# TMS320F280049 register map
Vendor: Texas Instruments; Series: C2000 F28004x; File version: 0.2.0-generated
Registers are 16-bit, read-write, reset 0x0 unless marked. A register's access mark holds for its fields unless they carry their own. Offsets are from the block's base; [hi:lo] are bit positions; 'fields as' and 'values as' point back to an identical list.

## PGA1REGS — PGA Registers
Base 0x0000B600
Same registers: PGA2REGS 0x0000B620, PGA3REGS 0x0000B640, PGA4REGS 0x0000B660, PGA5REGS 0x0000B680, PGA6REGS 0x0000B6A0, PGA7REGS 0x0000B6C0
0x00 PGACTL 32-bit — PGA Control Register
  [9:7] GAIN — PGA gain setting
  [7:4] FILTRESSEL — Filter Resistor Select
  [0] PGAEN — PGA Enable
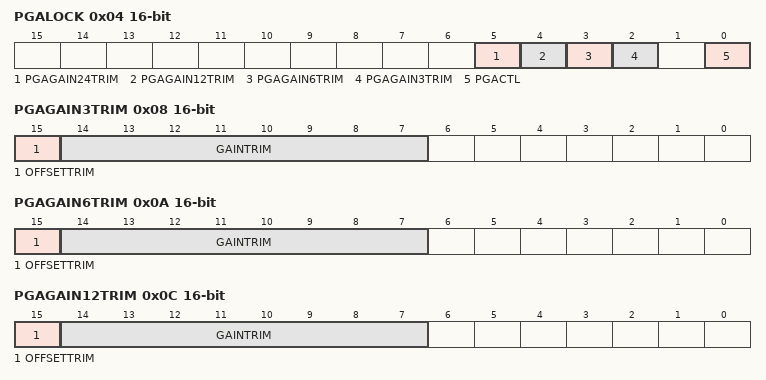
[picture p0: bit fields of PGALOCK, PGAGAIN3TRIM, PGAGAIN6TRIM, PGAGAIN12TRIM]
0x04 PGALOCK
  [5] PGAGAIN24TRIM — Lock bit for PGAGAIN24TRIM.
  [4] PGAGAIN12TRIM — Lock bit for PGAGAIN12TRIM.
  [3] PGAGAIN6TRIM — Lock bit for PGAGAIN6TRIM.
  [2] PGAGAIN3TRIM — Lock bit for PGAGAIN3TRIM.
  [0] PGACTL — Lock bit for PGACTL.
0x08 PGAGAIN3TRIM — PGA Gain Trim Register for a gain setting of 3
  [15] OFFSETTRIM — OFFSET TRIM value, when Gain setting is 3
  [14:7] GAINTRIM — Gain TRIM value, when gain setting is 3
0x0A PGAGAIN6TRIM — PGA Gain Trim Register for a gain setting of 6
  [15] OFFSETTRIM — OFFSET TRIM value, when Gain setting is 6
  [14:7] GAINTRIM — Gain TRIM value, when gain setting is 6
0x0C PGAGAIN12TRIM — PGA Gain Trim Register for a gain setting of 12
  [15] OFFSETTRIM — OFFSET TRIM value, when Gain setting is 12
  [14:7] GAINTRIM — Gain TRIM value, when gain setting is 12
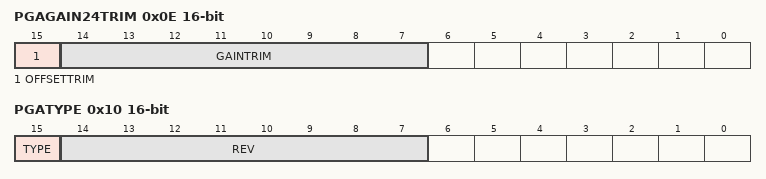
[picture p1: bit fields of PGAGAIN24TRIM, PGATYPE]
0x0E PGAGAIN24TRIM — PGA Gain Trim Register for a gain setting of 24
  [15] OFFSETTRIM — OFFSET TRIM value, when Gain setting is 24
  [14:7] GAINTRIM — Gain TRIM value, when gain setting is 24
0x10 PGATYPE
  [15] TYPE — PGA Type Field
  [14:7] REV — PGA Revision Field

## DACAREGS — DAC Registers
Base 0x0000B800
Same registers: DACBREGS 0x0000B820
0x00 DACREV — DAC Revision Register
  [14:7] REV
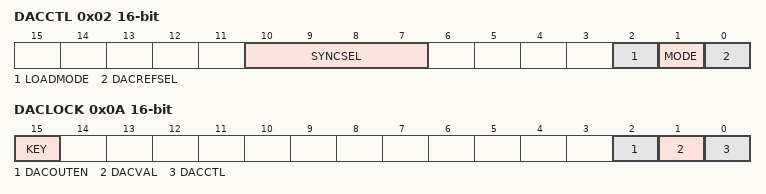
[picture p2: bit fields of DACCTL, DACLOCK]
0x02 DACCTL — DAC Control Register
  [10:7] SYNCSEL — DAC EPWMSYNCPER Select
  [2] LOADMODE — DACVALA Load Mode
  [1] MODE — DAC Mode Select
  [0] DACREFSEL — DAC Reference Select
0x04 DACVALA — DAC Value Register - Active
  [15:11] DACVALA — DAC Active Output Code
0x06 DACVALS — DAC Value Register - Shadow
  [15:11] DACVALS — DAC Shadow Output Code
0x08 DACOUTEN — DAC Output Enable Register
  [0] DACOUTEN — DAC Output Code
0x0A DACLOCK
  [15] KEY — DAC Register Lock Key
  [2] DACOUTEN — DAC Output Enable Register Lock
  [1] DACVAL — DAC Value Register Lock
  [0] DACCTL — DAC Control Register Lock
0x0C DACTRIM
  [14:7] OFFSET_TRIM — DAC Offset Trim

## CMPSS1REGS — CMPSS Registers
Base 0x0000B900
Same registers: CMPSS2REGS 0x0000B940, CMPSS3REGS 0x0000B980, CMPSS4REGS 0x0000B9C0, CMPSS5REGS 0x0000BA00, CMPSS6REGS 0x0000BA40, CMPSS7REGS 0x0000BA80
0x00 COMPCTL — CMPSS Comparator Control Register
  [15] COMPDACE — Comparator/DAC Enable
  [14] ASYNCLEN — Low Comparator Asynchronous Path Enable
  [14:13] CTRIPOUTLSEL — Low Comparator Trip Output Select
  [12:11] CTRIPLSEL — Low Comparator Trip Select
  [9] COMPLINV — Low Comparator Invert Select
  [8] COMPLSOURCE — Low Comparator Source Select
  [6] ASYNCHEN — High Comparator Asynchronous Path Enable
  [6:5] CTRIPOUTHSEL — High Comparator Trip Output Select
  [4:3] CTRIPHSEL — High Comparator Trip Select
  [1] COMPHINV — High Comparator Invert Select
  [0] COMPHSOURCE — High Comparator Source Select
0x02 COMPHYSCTL — CMPSS Comparator Hysteresis Control Register
  [6:3] COMPHYS — Comparator Hysteresis Trim
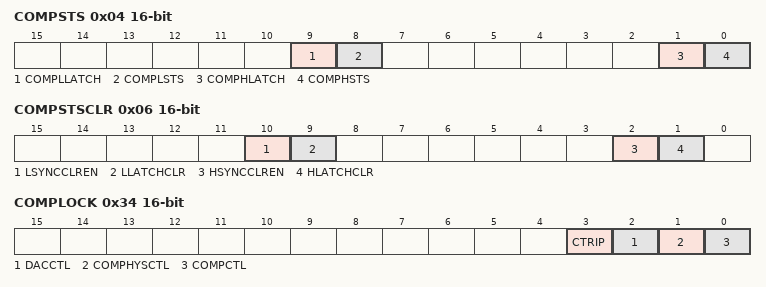
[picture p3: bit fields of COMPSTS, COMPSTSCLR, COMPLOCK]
0x04 COMPSTS — CMPSS Comparator Status Register
  [9] COMPLLATCH — Low Comparator Latched Status
  [8] COMPLSTS — Low Comparator Status
  [1] COMPHLATCH — High Comparator Latched Status
  [0] COMPHSTS — High Comparator Status
0x06 COMPSTSCLR — CMPSS Comparator Status Clear Register
  [10] LSYNCCLREN — Low Comparator EPWMSYNCPER Clear Enable
  [9] LLATCHCLR — Low Comparator Latched Status Clear
  [2] HSYNCCLREN — High Comparator EPWMSYNCPER Clear Enable
  [1] HLATCHCLR — High Comparator Latched Status Clear
0x08 COMPDACCTL — CMPSS DAC Control Register
  [15] FREESOFT — Free/Soft Emulation Bits
  [12] BLANKEN — EPWMBLANK Enable
  [14:11] BLANKSOURCE — EPWMBLANK Source Select
  [7] SWLOADSEL — Software Load Select
  [6] RAMPLOADSEL — Ramp Load Select
  [5] SELREF — DAC Reference Select
  [7:4] RAMPSOURCE — Ramp Generator Source Control
  [0] DACSOURCE — DAC Source Control
0x0C DACHVALS — CMPSS High DAC Value Shadow Register
  [15:11] DACVAL — DAC Value Control
0x0E DACHVALA — CMPSS High DAC Value Active Register
  [15:11] DACVAL — DAC Value Control
0x10 RAMPMAXREFA — CMPSS Ramp Max Reference Active Register
  [15] RAMPMAXREF — Ramp Maximum Reference Active
0x14 RAMPMAXREFS — CMPSS Ramp Max Reference Shadow Register
  [15] RAMPMAXREF — Ramp Maximum Reference Shadow
0x18 RAMPDECVALA — CMPSS Ramp Decrement Value Active Register
  [15] RAMPDECVAL — Ramp Decrement Value Active
0x1C RAMPDECVALS — CMPSS Ramp Decrement Value Shadow Register
  [15] RAMPDECVAL — Ramp Decrement Value Shadow
0x20 RAMPSTS — CMPSS Ramp Status Register
  [15] RAMPVALUE
0x24 DACLVALS — CMPSS Low DAC Value Shadow Register
  [15:11] DACVAL — DAC Value Control
0x26 DACLVALA — CMPSS Low DAC Value Active Register
  [15:11] DACVAL — DAC Value Control
0x28 RAMPDLYA — CMPSS Ramp Delay Active Register
  [15:12] DELAY — Ramp Delay Value
0x2A RAMPDLYS — CMPSS Ramp Delay Shadow Register
  [15:12] DELAY — Ramp Delay Value
0x2C CTRIPLFILCTL — CTRIPL Filter Control Register
  [15] FILINIT — Filter Initialization Bit
  [15:13] THRESH — Majority Voting Threshold
  [12:8] SAMPWIN — Sample Window
0x2E CTRIPLFILCLKCTL — CTRIPL Filter Clock Control Register
  [15:9] CLKPRESCALE — Sample Clock Prescale
0x30 CTRIPHFILCTL — CTRIPH Filter Control Register
  fields as CTRIPLFILCTL
0x32 CTRIPHFILCLKCTL — CTRIPH Filter Clock Control Register
  [15:9] CLKPRESCALE — Sample Clock Prescale
0x34 COMPLOCK — CMPSS Lock Register
  [3] CTRIP — CTRIP Lock
  [2] DACCTL — DACCTL Lock
  [1] COMPHYSCTL — COMPHYSCTL Lock
  [0] COMPCTL — COMPCTL Lock
